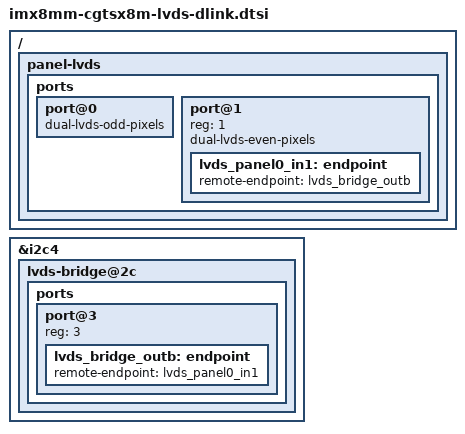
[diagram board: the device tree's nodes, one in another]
// SPDX-License-Identifier: (GPL-2.0+ OR MIT)
/*
 * Copyright (C) 2025 congatec GmbH
 * Author: Lukas Posadka <lukas.posadka@congatec.com>
 */

/dts-v1/;

#include "imx8mm-cgtsx8m-lvds.dtsi"

/ {
	panel-lvds {
		ports {
			port@0 {
				dual-lvds-odd-pixels;
			};

			port@1 {
				reg = <1>;
				dual-lvds-even-pixels;

				lvds_panel0_in1: endpoint {
					remote-endpoint = <&lvds_bridge_outb>;
				};
			};
		};
	};
};


&i2c4 {
	lvds-bridge@2c {
		ports {
			port@3 {
				reg = <3>;
	
				lvds_bridge_outb: endpoint {
					remote-endpoint = <&lvds_panel0_in1>;
				};
			};
		};
	};
};

